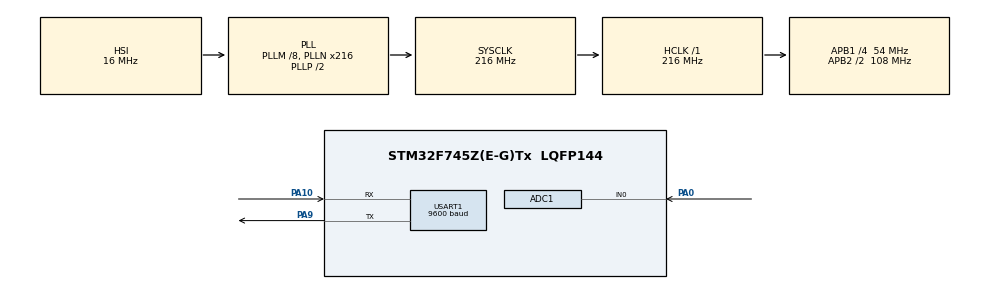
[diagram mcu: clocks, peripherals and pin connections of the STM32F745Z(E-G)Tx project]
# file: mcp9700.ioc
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ADC1.Channel-0\#ChannelRegularConversion=ADC_CHANNEL_0
ADC1.NbrOfConversionFlag=1
ADC1.Rank-0\#ChannelRegularConversion=1
ADC1.SamplingTime-0\#ChannelRegularConversion=ADC_SAMPLETIME_3CYCLES
ADC1.master=1
Mcu.Family=STM32F7
Mcu.Name=STM32F745Z(E-G)Tx
Mcu.Package=LQFP144
NVIC.PriorityGroup=NVIC_PRIORITYGROUP_4
NVIC.USART1_IRQn=true\:0\:0\:false\:false\:true\:true\:true\:true
PA0/WKUP.Signal=ADCx_IN0
PA10.Mode=Asynchronous
PA10.Signal=USART1_RX
PA13.Mode=Serial_Wire
PA13.Signal=SYS_JTMS-SWDIO
PA14.Mode=Serial_Wire
PA14.Signal=SYS_JTCK-SWCLK
PA9.Mode=Asynchronous
PA9.Signal=USART1_TX
PH0/OSC_IN.Mode=HSE-External-Oscillator
PH0/OSC_IN.Signal=RCC_OSC_IN
PH1/OSC_OUT.Mode=HSE-External-Oscillator
PH1/OSC_OUT.Signal=RCC_OSC_OUT
ProjectManager.HeapSize=0x200
ProjectManager.StackSize=0x400
ProjectManager.TargetToolchain=STM32CubeIDE
RCC.AHBFreq_Value=216000000
RCC.APB1CLKDivider=RCC_HCLK_DIV4
RCC.APB1Freq_Value=54000000
RCC.APB1TimFreq_Value=108000000
RCC.APB2CLKDivider=RCC_HCLK_DIV2
RCC.APB2Freq_Value=108000000
RCC.APB2TimFreq_Value=216000000
RCC.CortexFreq_Value=216000000
RCC.HCLKFreq_Value=216000000
RCC.HSE_VALUE=25000000
RCC.HSI_VALUE=16000000
RCC.LSE_VALUE=32768
RCC.PLLM=8
RCC.PLLN=216
RCC.SYSCLKFreq_VALUE=216000000
RCC.SYSCLKSource=RCC_SYSCLKSOURCE_PLLCLK
RCC.USBFreq_Value=216000000
RCC.VCOOutputFreq_Value=432000000
SH.ADCx_IN0.0=ADC1_IN0,IN0
USART1.BaudRate=9600
USART1.VirtualMode-Asynchronous=VM_ASYNC
board=custom

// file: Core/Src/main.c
/* USER CODE BEGIN Header */
/**
  ******************************************************************************
  * @file           : main.c
  * @brief          : Main program body
  ******************************************************************************
  * @attention
  *
  * Copyright (c) 2024 STMicroelectronics.
  * All rights reserved.
  *
  * This software is licensed under terms that can be found in the LICENSE file
  * in the root directory of this software component.
  * If no LICENSE file comes with this software, it is provided AS-IS.
  *
  ******************************************************************************
  */
/* USER CODE END Header */
#include "main.h"
#include "adc.h"
#include "usart.h"
#include "gpio.h"

/* USER CODE BEGIN Includes */
#include "mcp9701.h"
#include "SEVENSEGMENT.h"
/* USER CODE END Includes */

/* USER CODE BEGIN PV */
const uint16_t measurementTime=300;
uint32_t count=0;
int16_t temp;

/* USER CODE END PV */

void SystemClock_Config(void);

int main(void)
{

  /* MCU Configuration--------------------------------------------------------*/

  /* Reset of all peripherals, Initializes the Flash interface and the Systick. */
  HAL_Init();

  /* Configure the system clock */
  SystemClock_Config();

  /* Initialize all configured peripherals */
  MX_GPIO_Init();
  MX_ADC1_Init();
  MX_USART1_UART_Init();
  /* USER CODE BEGIN 2 */
 mcp9701Init();
 display_Init();
	temp=mcpGetValue();
  /* USER CODE END 2 */

  /* Infinite loop */
  /* USER CODE BEGIN WHILE */
  while (1)
  {
	  if (count>measurementTime)
	  {
		  count=measurementTime;
	  }
	  count++;
	  if(count==measurementTime)
	  {
	  temp=mcpGetValue();
	  count=0;
	  RELAY_DRIVE(temp);
	  }

	  display_Write(temp);
    /* USER CODE END WHILE */

  }
}

void SystemClock_Config(void)
{
  RCC_OscInitTypeDef RCC_OscInitStruct = {0};
  RCC_ClkInitTypeDef RCC_ClkInitStruct = {0};

  /** Configure the main internal regulator output voltage
  */
  __HAL_RCC_PWR_CLK_ENABLE();
  __HAL_PWR_VOLTAGESCALING_CONFIG(PWR_REGULATOR_VOLTAGE_SCALE1);

  /** Initializes the RCC Oscillators according to the specified parameters
  * in the RCC_OscInitTypeDef structure.
  */
  RCC_OscInitStruct.OscillatorType = RCC_OSCILLATORTYPE_HSI;
  RCC_OscInitStruct.HSIState = RCC_HSI_ON;
  RCC_OscInitStruct.HSICalibrationValue = RCC_HSICALIBRATION_DEFAULT;
  RCC_OscInitStruct.PLL.PLLState = RCC_PLL_ON;
  RCC_OscInitStruct.PLL.PLLSource = RCC_PLLSOURCE_HSI;
  RCC_OscInitStruct.PLL.PLLM = 8;
  RCC_OscInitStruct.PLL.PLLN = 216;
  RCC_OscInitStruct.PLL.PLLP = RCC_PLLP_DIV2;
  RCC_OscInitStruct.PLL.PLLQ = 2;
  if (HAL_RCC_OscConfig(&RCC_OscInitStruct) != HAL_OK)
  {
    Error_Handler();
  }

  /** Activate the Over-Drive mode
  */
  if (HAL_PWREx_EnableOverDrive() != HAL_OK)
  {
    Error_Handler();
  }

  /** Initializes the CPU, AHB and APB buses clocks
  */
  RCC_ClkInitStruct.ClockType = RCC_CLOCKTYPE_HCLK|RCC_CLOCKTYPE_SYSCLK
                              |RCC_CLOCKTYPE_PCLK1|RCC_CLOCKTYPE_PCLK2;
  RCC_ClkInitStruct.SYSCLKSource = RCC_SYSCLKSOURCE_PLLCLK;
  RCC_ClkInitStruct.AHBCLKDivider = RCC_SYSCLK_DIV1;
  RCC_ClkInitStruct.APB1CLKDivider = RCC_HCLK_DIV4;
  RCC_ClkInitStruct.APB2CLKDivider = RCC_HCLK_DIV2;

  if (HAL_RCC_ClockConfig(&RCC_ClkInitStruct, FLASH_LATENCY_7) != HAL_OK)
  {
    Error_Handler();
  }
}

void Error_Handler(void)
{
  __disable_irq();
  while (1)
  {
  }
}
